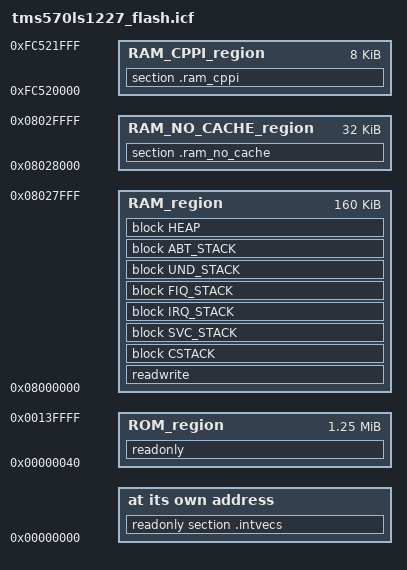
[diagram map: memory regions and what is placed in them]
/*###ICF### Section handled by ICF editor, don't touch! ****/
/*-Editor annotation file-*/
/* IcfEditorFile="$TOOLKIT_DIR$\config\ide\IcfEditor\a_v1_0.xml" */
/*-Specials-*/
define symbol __ICFEDIT_intvec_start__ = 0x00000000;
/*-Memory Regions-*/
define symbol __ICFEDIT_region_ROM_start__          = 0x00000040;
define symbol __ICFEDIT_region_ROM_end__            = 0x0013FFFF;
define symbol __ICFEDIT_region_RAM_start__          = 0x08000000;
define symbol __ICFEDIT_region_RAM_end__            = 0x08027FFF;
define symbol __ICFEDIT_region_RAM_NO_CACHE_start__ = 0x08028000;
define symbol __ICFEDIT_region_RAM_NO_CACHE_end__   = 0x0802FFFF;
define symbol __ICFEDIT_region_RAM_CPPI_start__     = 0xFC520000;
define symbol __ICFEDIT_region_RAM_CPPI_end__       = 0xFC521FFF;
/*-Sizes-*/
define symbol __ICFEDIT_size_cstack__   = 0x1000;
define symbol __ICFEDIT_size_svcstack__ = 0x100;
define symbol __ICFEDIT_size_irqstack__ = 0x100;
define symbol __ICFEDIT_size_fiqstack__ = 0x100;
define symbol __ICFEDIT_size_undstack__ = 0x100;
define symbol __ICFEDIT_size_abtstack__ = 0x100;
define symbol __ICFEDIT_size_heap__     = 0x18000;
/**** End of ICF editor section. ###ICF###*/

define memory mem with size = 4G;
define region ROM_region          = mem:[from __ICFEDIT_region_ROM_start__   to __ICFEDIT_region_ROM_end__];
define region RAM_region          = mem:[from __ICFEDIT_region_RAM_start__   to __ICFEDIT_region_RAM_end__];
define region RAM_NO_CACHE_region = mem:[from __ICFEDIT_region_RAM_NO_CACHE_start__ to __ICFEDIT_region_RAM_NO_CACHE_end__];
define region RAM_CPPI_region     = mem:[from __ICFEDIT_region_RAM_CPPI_start__ to __ICFEDIT_region_RAM_CPPI_end__];

define block CSTACK    with alignment = 8, size = __ICFEDIT_size_cstack__   { };
define block SVC_STACK with alignment = 8, size = __ICFEDIT_size_svcstack__ { };
define block IRQ_STACK with alignment = 8, size = __ICFEDIT_size_irqstack__ { };
define block FIQ_STACK with alignment = 8, size = __ICFEDIT_size_fiqstack__ { };
define block UND_STACK with alignment = 8, size = __ICFEDIT_size_undstack__ { };
define block ABT_STACK with alignment = 8, size = __ICFEDIT_size_abtstack__ { };
define block HEAP      with alignment = 8, size = __ICFEDIT_size_heap__     { };

initialize by copy { readwrite };
do not initialize  { section .noinit };

place at address mem:__ICFEDIT_intvec_start__ { readonly section .intvecs };

place in ROM_region { readonly };
place in RAM_region { readwrite };
place in RAM_region { block CSTACK, block SVC_STACK, block IRQ_STACK, block FIQ_STACK, block UND_STACK, block ABT_STACK };
place in RAM_region { block HEAP };
place in RAM_NO_CACHE_region { section .ram_no_cache };
place in RAM_CPPI_region { section .ram_cppi };
